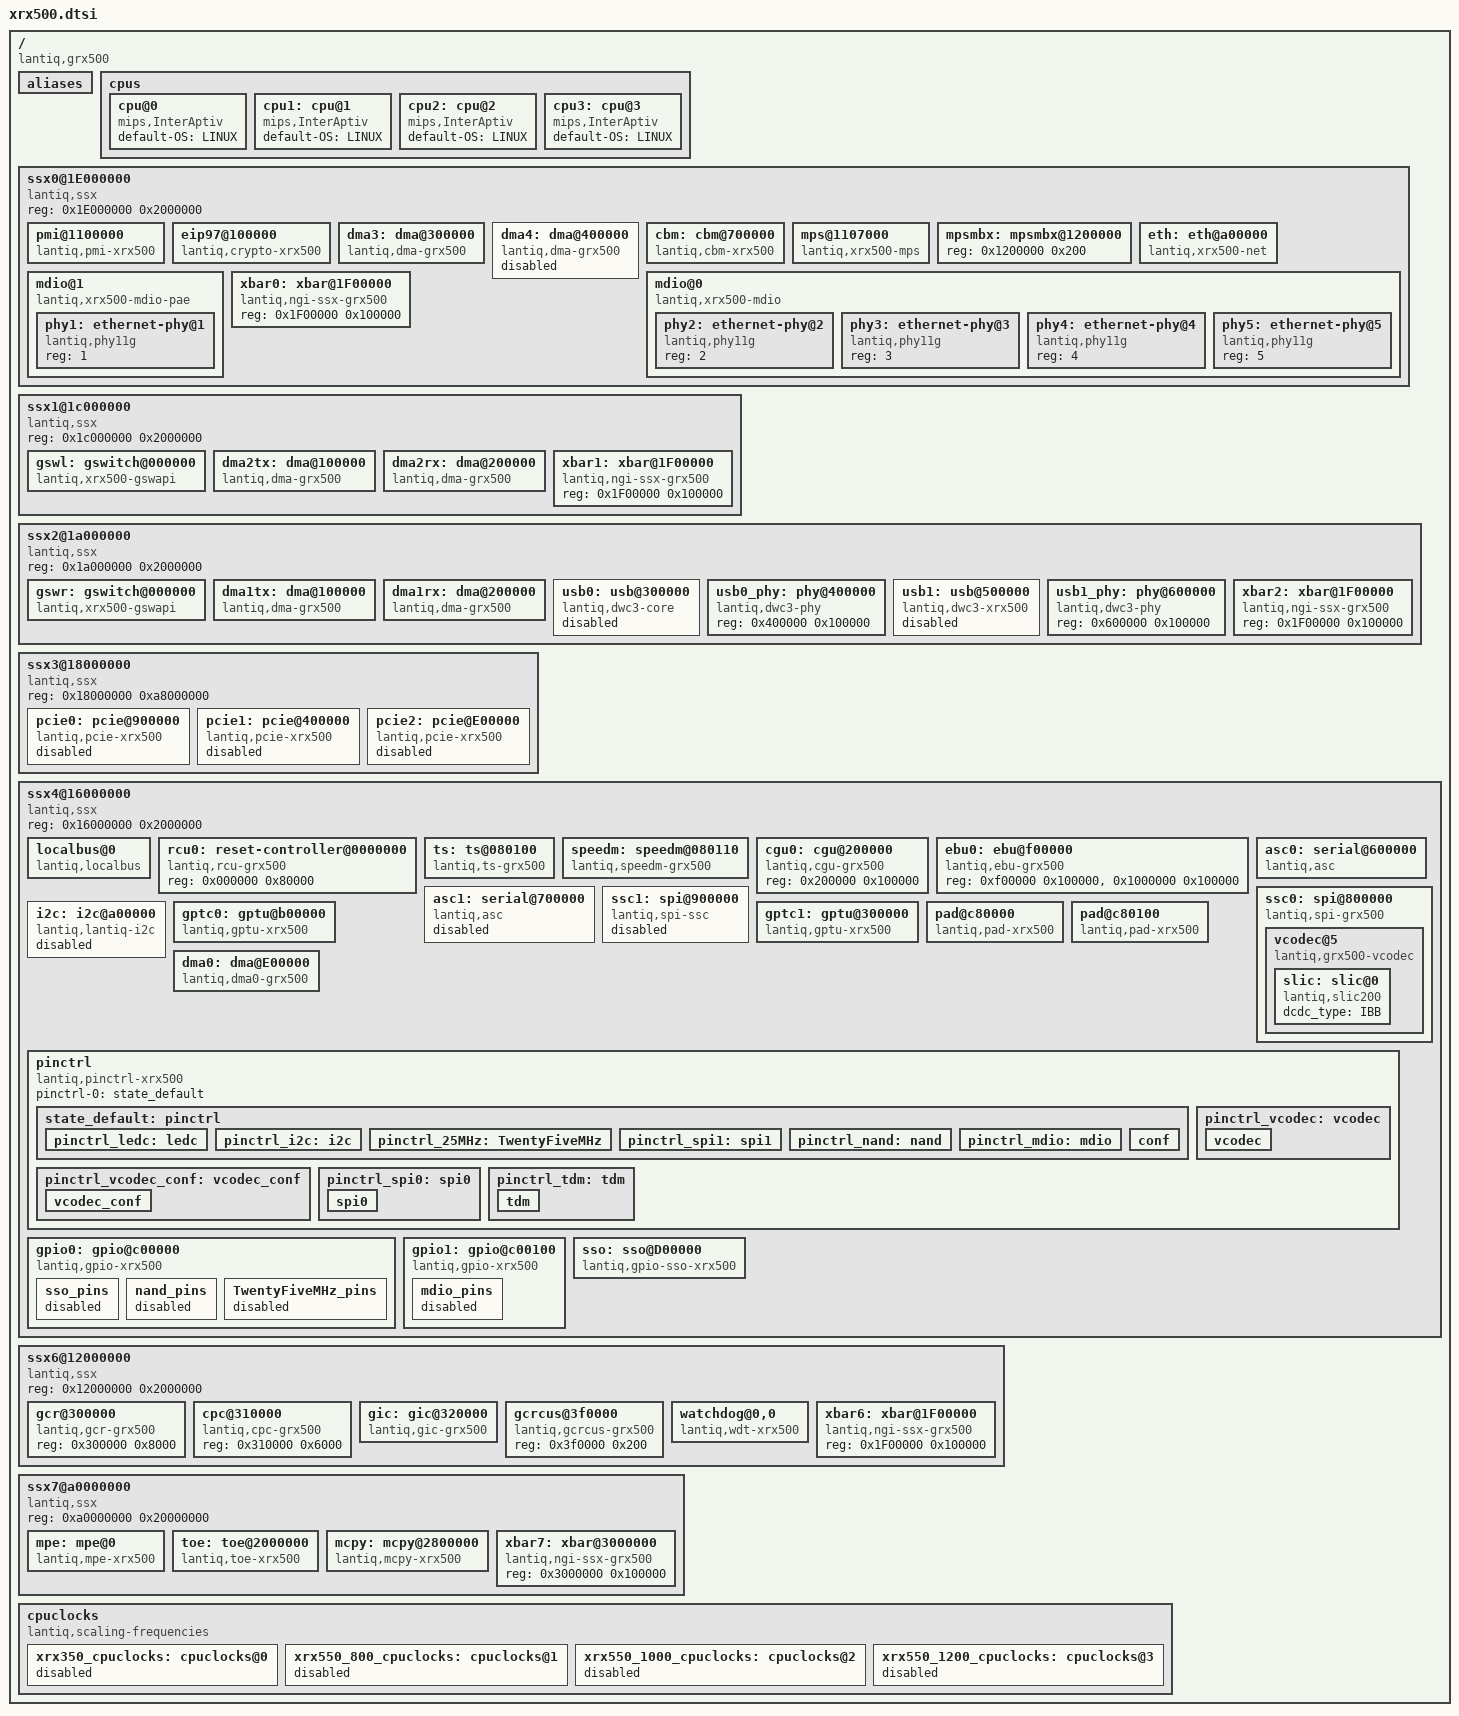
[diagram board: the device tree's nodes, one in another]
/ {
	#address-cells = <1>;
	#size-cells = <1>;
	compatible = "lantiq,grx500","lantiq,xrx500"; 
	
	aliases {
		serial0 = &asc0;
		serial1 = &asc1;
		dma0    = &dma0;
		dma1    = &dma1tx;
		dma2    = &dma1rx;
		dma3    = &dma2tx;
		dma4    = &dma2rx;
		dma5    = &dma3;
		dma6    = &dma4;
		pcie0   = &pcie0;
		pcie1   = &pcie1;
		pcie2   = &pcie2;
		usb0	= &usb0;
		usb1	= &usb1;
		spi1 	= &ssc1;
		xbar0 	= &xbar0;
		xbar1 	= &xbar1;
		xbar2 	= &xbar2;
		xbar6 	= &xbar6;
		xbar7 	= &xbar7;
		usb0_phy = &usb0_phy;
		usb1_phy = &usb1_phy;
	};

	cpus {
		cpu@0 {
			compatible = "mips,InterAptiv";
			default-OS = "LINUX";
		};
		cpu1: cpu@1 {
			compatible = "mips,InterAptiv";
			default-OS = "LINUX";
		};
		cpu2: cpu@2 {
			compatible = "mips,InterAptiv";
			default-OS = "LINUX";
		};
		cpu3: cpu@3 {
			compatible = "mips,InterAptiv";
			default-OS = "LINUX";
		};
	};

	ssx0@1E000000{ 
		#address-cells = <1>;
		#size-cells = <1>;
		compatible = "lantiq,ssx", "simple-bus";
		reg = <0x1E000000 0x2000000>;
		ranges = <0x0 0x1E000000 0x02000000>;
	
		pmi@1100000 {
			compatible = "lantiq,pmi-xrx500";
			reg = <0x1100000 0x100>;
			interrupt-parent = <&gic>;
			interrupts = <102>;
		};

		eip97@100000 {
			compatible = "lantiq,crypto-xrx500";
			reg = <0x100000 0x100000>;
			interrupt-parent = <&gic>;
			interrupts = <97 98 99>;
		};

		dma3: dma@300000 {
			compatible = "lantiq,dma-grx500";
			reg = <0x300000 0x100000>;
			interrupt-parent = <&gic>;
			interrupts = <77>;
			lantiq,dma-pkt-arb = <2>; /* 0 - burst, 1 - mulitburst, 2 - pkt */
			lantiq,dma-burst = <16>; /* 2, 4, 8, 16 */
			lantiq,dma-polling-cnt = <24>;
			lantiq,dma-chan-fc = <0>;
			lantiq,dma-desc-fod = <0>;
			lantiq,dma-desc-in-sram = <1>;
			lantiq,dma-drb = <0>;
			lantiq,dma-byte-en = <1>;
			lantiq,budget = <20>;
		};

		dma4: dma@400000 {
			status = "disabled";
			compatible = "lantiq,dma-grx500";
			reg = <0x400000 0x100000>;
			interrupt-parent = <&gic>;
			interrupts = <78>;
			lantiq,dma-pkt-arb = <2>; /* 0 - burst, 1 - mulitburst, 2 - pkt */
			lantiq,dma-burst = <16>; /* 2, 4, 8, 16 */
			lantiq,dma-polling-cnt = <24>;
			lantiq,dma-chan-fc = <0>;
			lantiq,dma-desc-fod = <0>;
			lantiq,dma-desc-in-sram = <0>;
			lantiq,dma-drb = <0>;

		};
		cbm: cbm@700000{ 
			status = "ok";
			compatible = "lantiq,cbm-xrx500";
			reg = < 0x700000 0x1000   /*TMU*/
				0x710000 0x10000 /*CBM*/
				0x720000 0x4000 /*QIDT*/
				0x730000 0x14000 /*SBIM*/
				0x750000 0x400 /*QEQCNTR*/
				0x750800 0x400 /*QDQCNTR*/
				0x760000 0x10000 /*LS*/
				0x780000 0x20000 /*CBM EQM*/
				0x7C0000 0x30000 /*CBM DQM*/
				0x800000 0x100000 /*FSQM0*/
				0x900000 0x100000 /*FSQM1*/
				0x500000 0x100000 /*CBM DMA DESC*/
				>;
				interrupt-parent = <&gic>;
				interrupts = <182 186 187 188 189>;
				
		};

	        mps@1107000 {
			compatible = "lantiq,xrx500-mps";
			reg = <0x1107000 0x400>;
			interrupt-parent = <&gic>;
			interrupts = <154 155>;
			lantiq,mbx = <&mpsmbx>;
		};

		mpsmbx: mpsmbx@1200000 {
			reg = <0x1200000 0x200>;
		};

		eth:eth@a00000{
			#address-cells = <1>;
			#size-cells = <0>;
			compatible = "lantiq,xrx500-net";
			interrupt-parent = <&gic>;
			interrupts = <56 53>;
			lantiq,eth-rx-csum-offload = <1>;
		};
		mdio@0 {
			#address-cells = <1>;
			#size-cells = <0>;
			compatible = "lantiq,xrx500-mdio";

			phy2: ethernet-phy@2 {
				reg = <2>;
				compatible = "lantiq,phy11g", "ethernet-phy-ieee802.3-c22";
			};

			phy3: ethernet-phy@3 {
				reg = <3>;
				compatible = "lantiq,phy11g", "ethernet-phy-ieee802.3-c22";
			};

			phy4: ethernet-phy@4 {
				reg = <4>;
				compatible = "lantiq,phy11g", "ethernet-phy-ieee802.3-c22";
			};

			phy5: ethernet-phy@5 {
				reg = <5>;
				compatible = "lantiq,phy11g", "ethernet-phy-ieee802.3-c22";
			};
		};

		mdio@1 {
			#address-cells = <1>;
			#size-cells = <0>;
			compatible = "lantiq,xrx500-mdio-pae";

			phy1: ethernet-phy@1 {
				reg = <1>;
				compatible = "lantiq,phy11g", "ethernet-phy-ieee802.3-c22";
			};

		};

		xbar0: xbar@1F00000 {
			compatible = "lantiq,ngi-ssx-grx500";
			reg = <0x1F00000 0x100000>;
		};
	};

	ssx1@1c000000 {
		#address-cells = <1>;
		#size-cells = <1>;
		compatible = "lantiq,ssx", "simple-bus"; 
		reg = <0x1c000000 0x2000000>;
		ranges = <0x0 0x1c000000 0x02000000>;

		gswl: gswitch@000000 {
			compatible = "lantiq,xrx500-gswapi", "lantiq,xway-gswapi"; 
			reg = <0x000000 0x3000>;
			lantiq,gsw-devid = <0>;
		};

		dma2tx: dma@100000 {
			compatible = "lantiq,dma-grx500";
			reg = <0x100000 0x100000>;
			interrupt-parent = <&gic>;
			interrupts = <75>;
			lantiq,dma-pkt-arb = <2>; /* 0 - burst, 1 - mulitburst, 2 - pkt */
			lantiq,dma-burst = <16>; /* 2, 4, 8, 16 */
			lantiq,dma-polling-cnt = <24>;
			lantiq,dma-chan-fc = <1>;
			lantiq,dma-desc-fod = <1>;
			lantiq,dma-desc-in-sram = <0>;
			lantiq,dma-drb = <0>;
			lantiq,dma-byte-en = <1>;
			lantiq,budget = <20>;
		};

		dma2rx: dma@200000 {
			compatible = "lantiq,dma-grx500";
			reg = <0x200000 0x100000>;
			interrupt-parent = <&gic>;
			interrupts = <76>;
			lantiq,dma-pkt-arb = <2>; /* 0 - burst, 1 - mulitburst, 2 - pkt */
			lantiq,dma-burst = <16>; /* 2, 4, 8, 16 */
			lantiq,dma-polling-cnt = <24>;
			lantiq,dma-chan-fc = <0>;
			lantiq,dma-desc-fod = <1>;
			lantiq,dma-desc-in-sram = <1>;
			lantiq,dma-drb = <0>;
			lantiq,dma-byte-en = <1>;
			lantiq,budget = <20>;
		};

		xbar1: xbar@1F00000 {
			compatible = "lantiq,ngi-ssx-grx500";
			reg = <0x1F00000 0x100000>;
		};
	};

	ssx2@1a000000 {
		#address-cells = <1>;
		#size-cells = <1>;
		compatible = "lantiq,ssx", "simple-bus";
		reg = <0x1a000000 0x2000000>;
		ranges = <0x0 0x1a000000 0x02000000>;

		gswr: gswitch@000000 {
			compatible =  "lantiq,xrx500-gswapi","lantiq,xway-gswapi"; 
			reg = <0x000000 0x3000>;
			lantiq,gsw-devid = <1>;
		};

		dma1tx: dma@100000 {
			compatible = "lantiq,dma-grx500";
			reg = <0x100000 0x100000>;
			interrupt-parent = <&gic>;
			interrupts = <73>;
			lantiq,dma-pkt-arb = <2>; /* 0 - burst, 1 - mulitburst, 2 - pkt */
			lantiq,dma-burst = <16>; /* 2, 4, 8, 16 */
			lantiq,dma-polling-cnt = <108>;
			lantiq,dma-chan-fc = <1>;
			lantiq,dma-desc-fod = <1>;
			lantiq,dma-desc-in-sram = <1>; /* A11 - 0, A21 - 1*/
			lantiq,dma-drb = <0>;
			lantiq,dma-byte-en = <1>;
			lantiq,budget = <20>;
			lantiq,dma-lab-cnt = <2>; /* 0, 1, 2, 3 */
		};

		dma1rx: dma@200000 {
			compatible = "lantiq,dma-grx500";
			reg = <0x200000 0x100000>;
			interrupt-parent = <&gic>;
			interrupts = <74>;
			lantiq,dma-pkt-arb = <2>; /* 0 - burst, 1 - mulitburst, 2 - pkt */
			lantiq,dma-burst = <16>; /* 2, 4, 8, 16 */
			lantiq,dma-polling-cnt = <24>;
			lantiq,dma-chan-fc = <0>;
			lantiq,dma-desc-fod = <1>;
			lantiq,dma-desc-in-sram = <0>;
			lantiq,dma-drb = <0>;
			lantiq,dma-byte-en = <0>;
			lantiq,budget = <20>;
		};

		usb0:usb@300000 {
			compatible = "lantiq,dwc3-core";
			reg = <0x300000 0x100000>;
			interrupt-parent = <&gic>;
			interrupts = <62>;
			phys = <&usb0_phy>;
			status = "disabled";
		};

		usb0_phy:phy@400000 {
			compatible = "lantiq,dwc3-phy";
			reg = <0x400000 0x100000>;
		};
		
		usb1:usb@500000 {
			compatible = "lantiq,dwc3-xrx500","lantiq,dwc3-core";
			reg = <0x500000 0x100000>;
			interrupt-parent = <&gic>;
			interrupts = <91>;
			phys = <&usb1_phy>;
			status = "disabled";
		};

		usb1_phy:phy@600000 {
			compatible = "lantiq,dwc3-phy";
			reg = <0x600000 0x100000>;
		};

		xbar2: xbar@1F00000 {
			compatible = "lantiq,ngi-ssx-grx500";
			reg = <0x1F00000 0x100000>;
		};
	};

	ssx3@18000000 {
		#address-cells = <1>;
		#size-cells = <1>;
		compatible = "lantiq,ssx", "simple-bus";
		reg = <0x18000000 0xa8000000>;
		ranges = <0x0 0x18000000 0xa8000000>;
		
		pcie0:pcie@900000 {
			status = "disabled";
			compatible = "lantiq,pcie-xrx500";
			device_type = "pci";
			#address-cells = <3>;
			#size-cells = <2>;
			reg = < 
				0x900000 0x100000 /* RC controller */
				0xA3000000 0x800000 /* Cfg*/
				0x800000 0x100000 /* App logic */
				0x500000 0x100000 /* PCIe PHY Reg */
				0x600000 0x100000 /* MSI addr space */
				0x700000 0x100000 /* MSI PIC */
			>;
			reg-names = "csr", "cfg", "app", "phy", "msi", "pic";
			interrupt-parent = <&gic>;
			interrupts = <136 137 138 139 140 141 142 143 160>;
			interrupt-names = "msi0", "msi1", "msi2", "msi3", "msi4", "msi5", "msi6", "msi7", "ir";
			#interrupt-cells = <1>;
			interrupt-map-mask = <0 0 0 0x7>;
			interrupt-map = <0 0 0 1 &gic  144>,
					<0 0 0 2 &gic  145>,
					<0 0 0 3 &gic  146>,
					<0 0 0 4 &gic  147>;
			ranges = <0x02000000 0 0xa0000000 0xa0000000 0 0x03000000    /* Non-pretechable memory 32bit */
				  0x01000000 0 0xa3800000 0xa3800000 0 0x00100000    /* Downsream I/O */ 
				 >;

			resets = <&rcu0 12>; 
			reset-names = "phy";
			lantiq,inbound-shift = <5>;
			lantiq,outbound-shift = <4>;
			lantiq,clkout = <22>;
		};

		pcie1:pcie@400000 {
			status = "disabled";
			compatible = "lantiq,pcie-xrx500";
			device_type = "pci";
			#address-cells = <3>;
			#size-cells = <2>;
			reg = <
				0x400000 0x100000 /* RC controller */
				0x9f000000 0x800000 /* Cfg*/
				0x300000 0x100000 /* App logic */
				0x000000 0x100000 /* PCIe PHY Reg */
				0x100000 0x100000 /* MSI phy space */
				0x200000 0x100000 /* MSI PIC */
				
			>;
			reg-names = "csr", "cfg", "app", "phy", "msi", "pic";
			interrupt-parent = <&gic>;
			interrupts = <45 46 47 48 49 50 51 52 57>;
			interrupt-names = "msi0", "msi1", "msi2", "msi3", "msi4", "msi5", "msi6", "msi7", "ir";
			#interrupt-cells = <1>;
			interrupt-map-mask = <0 0 0 0x7>;
			interrupt-map = <0 0 0 1 &gic  17>,
					<0 0 0 2 &gic  18>,
					<0 0 0 3 &gic  19>,
					<0 0 0 4 &gic  20>;
			ranges = < 0x02000000 0 0x9c000000 0x9c000000 0 0x03000000    /* Non-pretechable memory 32bit */
				   0x01000000 0 0x9f800000 0x9f800000 0 0x00100000    /* Downsream I/O */ 
				 >;
						
			resets = <&rcu0 13>; 
			reset-names = "phy";
			lantiq,inbound-shift = <9>;
			lantiq,outbound-shift = <8>;
			lantiq,clkout = <23>;
		};

		pcie2:pcie@E00000 {
			status = "disabled";
			compatible = "lantiq,pcie-xrx500";
			#address-cells = <3>;
			#size-cells = <2>;
			device_type = "pci";
			reg = <
				0xe00000 0x100000 /* RC controller */
				0xa7000000 0x800000 /* Cfg*/
				0xd00000 0x100000 /* App logic */
				0xa00000 0x100000 /* PCIe PHY Reg */
				0xb00000 0x100000 /* MSI addr space */
				0xc00000 0x100000 /* MSI PIC */
			>;
			reg-names = "csr", "cfg", "app", "phy", "msi", "pic";
			interrupt-parent = <&gic>;
			interrupts = <32 33 34 35 36 37 38 39 63>;
			interrupt-names = "msi0", "msi1", "msi2", "msi3", "msi4", "msi5", "msi6", "msi7", "ir";
			#interrupt-cells = <1>;
			interrupt-map-mask = <0 0 0 0x7>;
			interrupt-map = <0 0 0 1 &gic  163>,
					<0 0 0 2 &gic  164>,
					<0 0 0 3 &gic  165>,
					<0 0 0 4 &gic  166>;
			ranges = < 0x02000000 0 0xa4000000 0xa4000000 0 0x03000000    /* Non-pretechable memory 32bit */
				   0x01000000 0 0xa7800000 0xa7800000 0 0x00100000    /* Downsream I/O */ 
				 >;
			resets = <&rcu0 10>; 
			reset-names = "phy";
			lantiq,inbound-shift = <13>;
			lantiq,outbound-shift = <12>;
			lantiq,clkout = <24>;
		};
	};

	ssx4@16000000 {
		#address-cells = <1>;
		#size-cells = <1>;
		compatible = "lantiq,ssx", "simple-bus";
		reg = <0x16000000 0x2000000>;
		ranges = <0x0 0x16000000 0x02000000>;

		localbus@0 {
			#address-cells = <2>;
			#size-cells = <1>;
			ranges = <0 0 0x1400000 0xc00000 /* addrsel0 */
			1 0 0x1c00000 0x100000>; /* addsel1 */
			compatible = "lantiq,localbus", "simple-bus";
		};

		rcu0: reset-controller@0000000 {
			compatible = "lantiq,rcu-grx500", "lantiq,rcu-xrx500"; 
			reg = <0x000000 0x80000>;
			#reset-cells = <1>; 
		};

		ts: ts@080100 {
			compatible = "lantiq,ts-grx500" , "lantiq,ts-xrx500"; 
			reg = <0x080100 0x0C>;
			interrupt-parent = <&gic>;
			interrupts = <27>;
			lantiq,numofsensors = <0x2>;
		}; 

		speedm: speedm@080110 {
			compatible = "lantiq,speedm-grx500" , "lantiq,speedm-xrx500"; 
			reg = <0x080110 0x0C>;
			lantiq,thresholds_lvt = <1 10000 1 10000 1 10000>;
			lantiq,thresholds_svt = <1000 3350 3351 4000 4001 8000>;
			lantiq,sample_rate_svt = <255>;
			lantiq,sample_rate_lvt = <255>;
		}; 

		cgu0: cgu@200000 {
			compatible = "lantiq,cgu-grx500", "lantiq,cgu-xrx500";
			reg = <0x200000 0x100000>;
		};

		ebu0: ebu@f00000 {
			compatible = "lantiq,ebu-grx500", "lantiq,ebu-xrx500"; 
			reg = <0xf00000 0x100000>,
				<0x1000000 0x100000>; 
			reg-names = "ebunand_reg", "hsnand_reg";
		};

		asc0: serial@600000 {
			compatible = "lantiq,asc";
			reg = <0x600000 0x100000>;
			interrupt-parent = <&gic>;
			interrupts = <111 113 114>;
		};

		asc1: serial@700000 {
			compatible = "lantiq,asc";
			reg = <0x700000 0x100000>;
			interrupt-parent = <&gic>;
			interrupts = <84 86 87>;
			status = "disabled";
		};

		ssc0: spi@800000 {
			compatible = "lantiq,spi-grx500","lantiq,spi-lantiq-ssc";
			reg = <0x800000 0x400>;
			interrupt-parent = <&gic>;
			interrupts = <22 23 24>;
			#address-cells = <1>;
			#size-cells = <0>;

			vcodec@5 {
				compatible = "lantiq,grx500-vcodec";
				spi-max-frequency = <8000000>;
				reg = <5>;
				interrupts = <217>;
				interrupt-parent = <&gic>;
				pinctrl-names = "default";
				pinctrl-0 = <&pinctrl_vcodec &pinctrl_vcodec_conf>;
				slic: slic@0 {
					compatible = "lantiq,slic200";
					dcdc_type = "IBB";
				};
			};
		};

		ssc1: spi@900000 {
			compatible = "lantiq,spi-ssc";
			reg = <0x900000 0x400>;
			interrupt-parent = <&gic>;
			interrupts = <107 108 109>;
			#address-cells = <1>;
			#size-cells = <1>;
			lantiq,ssc-port = <1>;
			status = "disabled";
			legacy,cs-api-port = <1>;
		};

		i2c: i2c@a00000 {
			#address-cells = <1>;
			#size-cells = <0>;
			status = "disabled";
			compatible = "lantiq,lantiq-i2c";
			reg = <0xa00000 0x10000>;
			interrupt-parent = <&gic>;
			interrupts = <41 40 31 44>;
			clock-frequency = <100000>;
		};

		gptc0: gptu@b00000 {
			compatible = "lantiq,gptu-xrx500";
			reg = <0xb00000 0x400>;
			interrupt-parent = <&gic>;
			interrupts = <126 127 128 129 130 131>;
		};

		gptc1: gptu@300000 {
			compatible = "lantiq,gptu-xrx500";
			reg = <0x300000 0x400>;
			interrupt-parent = <&gic>;
			interrupts = <168 169 170 171 172 173>;
		};

		pad@c80000{
			compatible = "lantiq,pad-xrx500";
			lantiq,bank = <0>;
			reg = <0xc80000 0x100>;
		};

		pad@c80100{
			compatible = "lantiq,pad-xrx500";
			lantiq,bank = <1>;
			reg = <0xc80100 0x100>;
			lantiq,bbspi-en = <0>;
		};

		dma0: dma@E00000 {
			compatible = "lantiq,dma0-grx500", "lantiq,dma-xway";
			reg = <0xE00000 0x100000>;
			interrupt-parent = <&gic>;
			interrupts = <72>;
			lantiq,desc-num = <16>;
			lantiq,dma-burst = <2>;
			lantiq,dma-polling-cnt = <4>;
			lantiq,dma-drb = <1>;
			lantiq,budget = <20>;
		};

		pinctrl: pinctrl {	/*Change the label form gpio to pinctrl*/
			compatible = "lantiq,pinctrl-xrx500";
			pinctrl-names = "default";
			pinctrl-0 = <&state_default>;

			/* default pinctrl setting*/
			state_default: pinctrl {
				pinctrl_ledc: ledc {
					lantiq,groups = "ledc";
					lantiq,function = "ledc";
				};
				pinctrl_i2c: i2c {
					lantiq,groups = "i2c";
					lantiq,function = "i2c";
				};
				pinctrl_25MHz: TwentyFiveMHz {
					lantiq,groups = "25MHz";
					lantiq,function = "25MHz";
				};
				pinctrl_spi1: spi1 {
					lantiq,groups = "spi1", "spi1_cs0";
					lantiq,function = "spi1";
				};
				pinctrl_nand: nand {
					lantiq,groups = "nand cle", "nand ale", 
						"nand rd", "nand rdy",
						"nand d0", "nand d1",
						"nand d2", "nand d3",
						"nand d4", "nand d5",
						"nand d6", "nand d7",
						"nand cs1", "nand wr",
						"nand wp", "nand se";
					lantiq,function = "ebu";   
				};

				pinctrl_mdio: mdio {
					lantiq,groups = "mdio_l", "mdio_r";
					lantiq,function = "mdio";
				};

				conf {
					lantiq,pins = "io21", "io22", "io32", "io33", "io42", "io43";
					lantiq,open-drain = <1>;
				};
				
			};
			pinctrl_vcodec: vcodec {
					vcodec {
					lantiq,groups = "vcodec", "clkout0";
					lantiq,function = "vcodec";
					};
				};

			pinctrl_vcodec_conf: vcodec_conf {
				vcodec_conf {
					lantiq,pins = "io35";
					lantiq,pull = <0>;
				};
			};

			pinctrl_spi0: spi0 {
				spi0 {	
					lantiq,groups = "spi0", "spi0_cs1";
					lantiq,function = "spi0";
					};
			};
			pinctrl_tdm: tdm {
					tdm {
					lantiq,groups = "tdm";
					lantiq,function = "tdm";
					};
			};
		};
	
		gpio0: gpio@c00000 {
			compatible = "lantiq,gpio-xrx500";
			gpio-controller;
			#gpio-cells = <2>;
			reg = <0xc00000 0x80>;
			interrupt-controller;
			#interrupt-cells = <2>;
			interrupt-parent = <&gic>;
			interrupts = <180>;
			lantiq,bank = <0>;
			sso_pins: sso_pins {
				status = "disabled";
				hog-as-output;
				gpio = <4 5 6>;
			};
			nand_pins: nand_pins {
				status = "disabled";
				hog-as-output;
				gpio = <24 13 49 50 51 52 53 54 55 56 57 23 59 60 61>;
			};
			TwentyFiveMHz_pins: TwentyFiveMHz_pins {
				status = "disabled";
				hog-as-output;
				gpio = <3>;
			};
		};

		gpio1: gpio@c00100 {
			compatible = "lantiq,gpio-xrx500";
			gpio-controller;
			#gpio-cells = <2>;
			reg = <0xc00100 0x80>;
			interrupt-controller;
			#interrupt-cells = <2>;
			interrupt-parent = <&gic>;
			interrupts = <181>;
			lantiq,bank = <1>;
			mdio_pins: mdio_pins {
				status = "disabled";
				hog-as-output;
				gpio = <32 33 42 43>;
			};
		};

		sso: sso@D00000 {
			compatible = "lantiq,gpio-sso-xrx500";
			reg = <0xD00000 0x2CC>;
			#gpio-cells = <2>;
			gpio-controller;
		};
	};

	ssx6@12000000 {
		#address-cells = <1>;
		#size-cells = <1>;
		compatible = "lantiq,ssx", "simple-bus";
		reg = <0x12000000 0x2000000>;
		ranges = <0x0 0x12000000 0x02000000>;

		gcr@300000 {
			compatible = "lantiq,gcr-grx500";
			reg = <0x300000 0x8000>;
		};

		cpc@310000 {
			compatible = "lantiq,cpc-grx500";
			reg = <0x310000 0x6000>;
		};
	
		gic: gic@320000 {
			#interrupt-cells = <1>;
			interrupt-controller;
			compatible = "lantiq,gic-grx500";
			reg = <0x320000 0x20000>;
		};
		
		gcrcus@3f0000 {
			compatible = "lantiq,gcrcus-grx500";
			reg = <0x3f0000 0x200>;
		};

		watchdog@0,0 {
			#interrupt-cells = <1>;
			compatible = "lantiq,wdt-xrx500";
			reg = <0 0>;
			interrupt-parent = <&gic>;
			interrupts = <264>;
			timeout-sec = <5>;
		};

		xbar6: xbar@1F00000 {
			compatible = "lantiq,ngi-ssx-grx500";
			reg = <0x1F00000 0x100000>;
		};
	};

	ssx7@a0000000 {
		#address-cells = <1>;
		#size-cells = <1>;
		compatible = "lantiq,ssx", "simple-bus";
		reg = <0xa0000000 0x20000000>;
		ranges = <0x0 0xa0000000 0x20000000>;

		mpe: mpe@0 {
            		#address-cells = <1>;
            		#size-cells = <1>;
            		compatible = "lantiq,mpe-xrx500";
            		reg = <0x0 0x200000>;
            		dtlk_vpe_num = <1>;
        	};
        	
		toe: toe@2000000 {
			#address-cells = <1>;
			#size-cells = <1>;
			compatible = "lantiq,toe-xrx500";
			reg = <0x2000000 0x10000
				   0x2013000 0x4000>;
			interrupt-parent = <&gic>;
			interrupts = <79 80 81 82 83 190 191 192 193 194 195 196 197 198 199>;
		};

		mcpy: mcpy@2800000 {
			#address-cells = <1>;
			#size-cells = <1>;
			compatible = "lantiq,mcpy-xrx500";
			reg = <0x2800000 0x800000>;
			interrupt-parent = <&gic>;
			interrupts = <200 201 202 203 204 205 206 207 208 209 210 211 212 213 214 215 216>;
			interrupt-names = "yld0", "yld1", "yld2", "yld3", "yld4", "yld5", "yld6", "yld7", "irq0", "irq1", "irq2", "irq3", "irq4", "irq5", "irq6", "irq7";
			/* Prio (1 is high), reserved for which VPE. (-1 NO reserve), trank size, irq_interval,  Enable (1 is En) */
			/* Trunk size:  -1 - Default Value, 0-"512B", 1-"1KB", 2-"2KB", 3-"4KB", 4-"8KB", 5-"16KB", 6-"32KB", 7-"64KB" */
			/* IRQ interval: 0 - Default Value> */
			/* mcpy ch id from 0 to 7, default setting please refer to the mcpy driver source code */
			/* lantiq,mcpy-ch0 = <1 0 -1 0 1>;  set mcpy ch0 to high prio, reserved for vpe 0, defaut trunk size, default irq_interval, enable*/
			lantiq,mcpy-minlen = <64>;
			lantiq,umt0-dmacid = <7>;
			lantiq,umt1-dmacid = <8>;
			lantiq,umt2-dmacid = <9>;
			lantiq,umt3-dmacid = <10>;
		}; 

		xbar7: xbar@3000000 {
			compatible = "lantiq,ngi-ssx-grx500";
			reg = <0x3000000 0x100000>;
		};

	};	
	

	cpuclocks {
		compatible = "lantiq,scaling-frequencies";

		xrx350_cpuclocks: cpuclocks@0 {
			status = "disabled";
			lantiq,cpuclocks = <600000000 600000000 600000000 150000000>;
			lantiq,threshold_dp = <1 1 1 101>;
			lantiq,poll_period = <11>;
		}; 
	
		xrx550_800_cpuclocks: cpuclocks@1 {
			status = "disabled";
			lantiq,cpuclocks = <800000000 800000000 600000000 150000000>;
			lantiq,threshold_dp = <1 1 1 101>;
			lantiq,poll_period = <11>;
		}; 
	
		xrx550_1000_cpuclocks: cpuclocks@2 {
			status = "disabled";
			lantiq,cpuclocks = <1000000000 666666666 333333333 166666666>;
			lantiq,threshold_dp = <1 1 1 101>;
			lantiq,poll_period = <11>;
		};
		
		xrx550_1200_cpuclocks: cpuclocks@3 {
			status = "disabled";
			lantiq,cpuclocks = <1200000000 800000000 600000000 150000000>;
			lantiq,threshold_dp = <1 1 1 101>;
			lantiq,poll_period = <11>;
		};
	}; 
};
